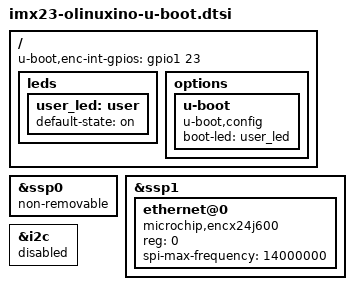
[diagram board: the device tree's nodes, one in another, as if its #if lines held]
// SPDX-License-Identifier: GPL-2.0+

/ {
	leds {
		user_led: user {
			default-state = "on";
		};
	};

	options {
		u-boot {
			compatible = "u-boot,config";
			boot-led = <&user_led>;
		};
	};
};

&ssp0 {
	non-removable;
};

#ifdef CONFIG_ENCX24J600
/ {
	u-boot,enc-int-gpios = <&gpio1 23 0>;
};

&ssp1 {
	ethernet@0 {
		compatible = "microchip,encx24j600";
		reg = <0>;
		spi-max-frequency = <14000000>;
	};
};

&i2c {
	status = "disabled";
};
#endif
